VERSION ""

NS_ :

BS_:

BU_:

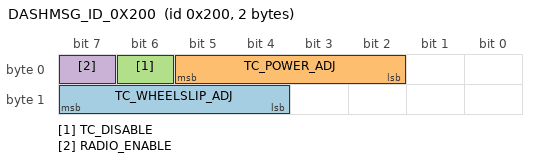
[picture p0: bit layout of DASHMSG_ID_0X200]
BO_ 512 DASHMSG_ID_0X200: 2 Vector__XXX
 SG_ TC_WHEELSLIP_ADJ : 15|4@0- (1,0) [-8|7] "" Vector__XXX
 SG_ TC_POWER_ADJ : 5|4@0- (1,0) [-8|7] "" Vector__XXX
 SG_ TC_DISABLE : 6|1@0+ (1,0) [0|1] "bool" Vector__XXX
 SG_ RADIO_ENABLE : 7|1@0+ (1,0) [0|1] "bool" Vector__XXX

BA_DEF_  "BusType" STRING ;
BA_DEF_DEF_  "BusType" "CAN";
